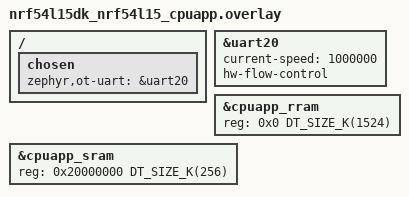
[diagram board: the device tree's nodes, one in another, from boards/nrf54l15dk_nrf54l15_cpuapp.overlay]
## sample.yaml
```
sample:
  description: Test OpenThread Co-Processor
  name: OpenThread Co-Processor sample

tests:
  sample.openthread.coprocessor:
    sysbuild: true
    build_only: true
    tags: ci_build sysbuild ci_samples_openthread
    platform_allow: >
      nrf52833dk/nrf52833
      nrf52840dk/nrf52840
      nrf52840dongle/nrf52840
      nrf21540dk/nrf52840
      nrf54l15dk/nrf54l15/cpuapp
      nrf54l15dk/nrf54l10/cpuapp
      nrf54l15dk/nrf54l05/cpuapp
      nrf54l15dk/nrf54l15/cpuapp/ns
    integration_platforms:
      - nrf52833dk/nrf52833
      - nrf52840dk/nrf52840
      - nrf21540dk/nrf52840
      - nrf52840dongle/nrf52840
      - nrf54l15dk/nrf54l15/cpuapp
      - nrf54l15dk/nrf54l10/cpuapp
      - nrf54l15dk/nrf54l05/cpuapp
      - nrf54l15dk/nrf54l15/cpuapp/ns
  sample.openthread.coprocessor.vendor_hook:
    sysbuild: true
    build_only: true
    tags: ci_build sysbuild ci_samples_openthread
    platform_allow: >
      nrf52833dk/nrf52833
      nrf52840dk/nrf52840
      nrf52840dongle/nrf52840
      nrf21540dk/nrf52840
      nrf54l15dk/nrf54l15/cpuapp
      nrf54l15dk/nrf54l10/cpuapp
      nrf54l15dk/nrf54l05/cpuapp
      nrf54l15dk/nrf54l15/cpuapp/ns
    extra_args: >
      SNIPPET="ci;logging;vendor_hook"
    integration_platforms:
      - nrf52833dk/nrf52833
      - nrf52840dk/nrf52840
      - nrf21540dk/nrf52840
      - nrf52840dongle/nrf52840
      - nrf54l15dk/nrf54l15/cpuapp
      - nrf54l15dk/nrf54l10/cpuapp
      - nrf54l15dk/nrf54l05/cpuapp
      - nrf54l15dk/nrf54l15/cpuapp/ns
  sample.openthread.coprocessor.usb:
    sysbuild: true
    build_only: true
    tags: ci_build sysbuild ci_samples_openthread
    platform_allow: >
      nrf52833dk/nrf52833
      nrf52840dk/nrf52840
      nrf21540dk/nrf52840
    extra_args: >
      SNIPPET="ci;usb"
    integration_platforms:
      - nrf52840dk/nrf52840
      - nrf52833dk/nrf52833
      - nrf21540dk/nrf52840
  sample.openthread.coprocessor.hci:
    sysbuild: true
    build_only: true
    tags: ci_build sysbuild ci_samples_openthread
    extra_args: >
      SNIPPET="ci;hci"
    platform_allow: >
      nrf52840dk/nrf52840
      nrf21540dk/nrf52840
    integration_platforms:
      - nrf52840dk/nrf52840
```

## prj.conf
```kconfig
#
# Copyright (c) 2020 Nordic Semiconductor
#
# SPDX-License-Identifier: LicenseRef-Nordic-5-Clause
#

# Set OpenThread NCP architecture
CONFIG_OPENTHREAD_COPROCESSOR=y
CONFIG_OPENTHREAD_COPROCESSOR_RCP=y

# Nordic feature set
CONFIG_OPENTHREAD_NORDIC_LIBRARY_RCP=y

CONFIG_NET_L2_OPENTHREAD=y

# Generic networking options
CONFIG_NETWORKING=y

# Increase Settings storage size
CONFIG_PM_PARTITION_SIZE_SETTINGS_STORAGE=0x8000

# Disable RTT
CONFIG_USE_SEGGER_RTT=n

# Disable GPIO
CONFIG_GPIO=n
```

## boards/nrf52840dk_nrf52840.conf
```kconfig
#
# Copyright (c) 2024 Nordic Semiconductor
#
# SPDX-License-Identifier: LicenseRef-Nordic-5-Clause
#

# Disable CC3XX entropy
CONFIG_HW_CC3XX=n
CONFIG_ENTROPY_CC3XX=n
```

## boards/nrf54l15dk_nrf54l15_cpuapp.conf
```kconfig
#
# Copyright (c) 2024 Nordic Semiconductor
#
# SPDX-License-Identifier: LicenseRef-Nordic-5-Clause
#

CONFIG_SPI_NOR=n

# Workaround required as Zephyr L2 implies usage of NVS backend for settings.
# It should be removed once the proper fix will be applied in Zephyr.
CONFIG_NVS=n
CONFIG_ZMS=y
CONFIG_SETTINGS_ZMS=y
```

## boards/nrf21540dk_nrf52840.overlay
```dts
/* Copyright (c) 2020 Nordic Semiconductor ASA
 *
 * SPDX-License-Identifier: LicenseRef-Nordic-5-Clause
 */

/* Default Zephyr configuration already provides GPIO support for FEM. */

&uart0 {
	current-speed = <1000000>;
	status = "okay";
	hw-flow-control;
};

&uart1 {
	current-speed = <1000000>;
	status = "okay";
};

/ {
	/*
	* In some default configurations within the nRF Connect SDK,
	* e.g. on nRF52840, the chosen zephyr,entropy node is &cryptocell.
	* This devicetree overlay ensures that default is overridden wherever it
	* is set, as this application uses the RNG node for entropy exclusively.
	*/
	chosen {
		zephyr,entropy = &rng;
		zephyr,ot-uart = &uart0;
	};
};
```

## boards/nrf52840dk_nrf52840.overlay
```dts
/* Copyright (c) 2020 Nordic Semiconductor ASA
 *
 * SPDX-License-Identifier: LicenseRef-Nordic-5-Clause
 */

&uart0 {
	current-speed = <1000000>;
	status = "okay";
	hw-flow-control;
};

&uart1 {
	current-speed = <1000000>;
	status = "okay";
};

/ {
	/*
	* In some default configurations within the nRF Connect SDK,
	* e.g. on nRF52840, the chosen zephyr,entropy node is &cryptocell.
	* This devicetree overlay ensures that default is overridden wherever it
	* is set, as this application uses the RNG node for entropy exclusively.
	*/
	chosen {
		zephyr,entropy = &rng;
		zephyr,ot-uart = &uart0;
	};
};
```

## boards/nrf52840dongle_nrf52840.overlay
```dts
/* Copyright (c) 2024 Nordic Semiconductor ASA
 *
 * SPDX-License-Identifier: LicenseRef-Nordic-5-Clause
 */

/ {
	/*
	 * nRF52840 dongle has pin P0.19 connected to reset. By setting it
	 * in `GPIO_OUTPUT_ACTIVE` mode, reset is pulled to GND,
	 * which results in device rebooting without skipping the bootloader.
	 * openthread_config node enables doing so using `reset bootloader` command.
	 */
	openthread_config: openthread {
		compatible = "openthread,config";
		bootloader-gpios = <&gpio0 19 GPIO_ACTIVE_LOW>;
	};

	chosen {
		zephyr,ot-uart = &cdc_acm_uart;
	};
};
```

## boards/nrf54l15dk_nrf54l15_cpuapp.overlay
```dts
/* Copyright (c) 2024 Nordic Semiconductor ASA
 *
 * SPDX-License-Identifier: LicenseRef-Nordic-5-Clause
 */

&uart20 {
    current-speed = <1000000>;
    status = "okay";
    hw-flow-control;
};

 / {
    chosen {
        zephyr,ot-uart = &uart20;
    };
};

// restore full RRAM and SRAM space - by default some parts are dedicated to FLPR
&cpuapp_rram {
	reg = <0x0 DT_SIZE_K(1524)>;
};

&cpuapp_sram {
	reg = <0x20000000 DT_SIZE_K(256)>;
	ranges = <0x0 0x20000000  DT_SIZE_K(256)>;
};
```

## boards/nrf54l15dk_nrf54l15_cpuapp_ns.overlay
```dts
/* Copyright (c) 2024 Nordic Semiconductor ASA
 *
 * SPDX-License-Identifier: LicenseRef-Nordic-5-Clause
 */

&uart20 {
	current-speed = <1000000>;
	status = "okay";
	hw-flow-control;
};

/ {
	chosen {
		zephyr,ot-uart = &uart20;
	};
};

// restore full RRAM and SRAM space - by default some parts are dedicated to FLPR
&cpuapp_rram {
	reg = <0x0 DT_SIZE_K(1524)>;
};

&cpuapp_sram {
	reg = <0x20000000 DT_SIZE_K(256)>;
	ranges = <0x0 0x20000000  DT_SIZE_K(256)>;
};
```

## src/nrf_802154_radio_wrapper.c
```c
/*
 * Copyright (c) 2020 Nordic Semiconductor ASA
 *
 * SPDX-License-Identifier: LicenseRef-Nordic-5-Clause
 */
#include "nrf_802154_radio_wrapper.h"
#include <nrf_802154.h>
#include <zephyr/device.h>
#include <zephyr/net/ieee802154_radio.h>

static const struct device *const radio_dev =
	DEVICE_DT_GET(DT_CHOSEN(zephyr_ieee802154));
static struct ieee802154_radio_api *radio_api;

bool nrf_802154_radio_wrapper_auto_ack_get(void)
{
	return nrf_802154_auto_ack_get();
}

void nrf_802154_radio_wrapper_auto_ack_set(bool enabled)
{
	nrf_802154_auto_ack_set(enabled);
}

uint16_t nrf_802154_radio_wrapper_hw_capabilities_get(void)
{
	__ASSERT_NO_MSG(device_is_ready(radio_dev));

	radio_api = (struct ieee802154_radio_api *)radio_dev->api;
	__ASSERT_NO_MSG(radio_api != NULL);

	return radio_api->get_capabilities(radio_dev);
}
```

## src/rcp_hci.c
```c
/*
 * Copyright (c) 2023 Nordic Semiconductor ASA
 *
 * SPDX-License-Identifier: LicenseRef-Nordic-5-Clause
 */

#include <errno.h>
#include <stddef.h>
#include <stdio.h>
#include <string.h>

#include <zephyr/arch/cpu.h>
#include <zephyr/sys/byteorder.h>
#include <zephyr/sys/util.h>

#include <zephyr/device.h>
#include <zephyr/init.h>
#include <zephyr/drivers/uart.h>

#include <zephyr/usb/usb_device.h>

#include <zephyr/net_buf.h>
#include <zephyr/bluetooth/bluetooth.h>
#include <zephyr/bluetooth/l2cap.h>
#include <zephyr/bluetooth/hci.h>
#include <zephyr/bluetooth/buf.h>
#include <zephyr/bluetooth/hci_raw.h>

LOG_MODULE_REGISTER(rcp_hci_module, CONFIG_OT_COPROCESSOR_LOG_LEVEL);

static const struct device *const hci_uart_dev = DEVICE_DT_GET(DT_CHOSEN(zephyr_bt_c2h_uart));
static K_THREAD_STACK_DEFINE(tx_thread_stack, CONFIG_BT_HCI_TX_STACK_SIZE);
static struct k_thread tx_thread_data;
static K_FIFO_DEFINE(tx_queue);

/* RX in terms of bluetooth communication */
static K_FIFO_DEFINE(uart_tx_queue);

#define H4_CMD 0x01
#define H4_ACL 0x02
#define H4_SCO 0x03
#define H4_EVT 0x04
#define H4_ISO 0x05

/* Receiver states. */
#define ST_IDLE	   0 /* Waiting for packet type. */
#define ST_HDR	   1 /* Receiving packet header. */
#define ST_PAYLOAD 2 /* Receiving packet payload. */
#define ST_DISCARD 3 /* Dropping packet. */

#define H4_DISCARD_LEN 33

static int h4_read(const struct device *uart, uint8_t *buf, size_t len)
{
	int rx = uart_fifo_read(uart, buf, len);

	LOG_DBG("read %d req %d", rx, len);

	return rx;
}

static bool valid_type(uint8_t type)
{
	return (type == H4_CMD) | (type == H4_ACL) | (type == H4_ISO);
}

/* Function expects that type is validated and only CMD, ISO or ACL will be used. */
static uint32_t get_len(const uint8_t *hdr_buf, uint8_t type)
{
	switch (type) {
	case H4_CMD:
		return ((const struct bt_hci_cmd_hdr *)hdr_buf)->param_len;
	case H4_ISO:
		return bt_iso_hdr_len(
			sys_le16_to_cpu(((const struct bt_hci_iso_hdr *)hdr_buf)->len));
	case H4_ACL:
		return sys_le16_to_cpu(((const struct bt_hci_acl_hdr *)hdr_buf)->len);
	default:
		LOG_ERR("Invalid type: %u", type);
		return 0;
	}
}

/* Function expects that type is validated and only CMD, ISO or ACL will be used. */
static int hdr_len(uint8_t type)
{
	switch (type) {
	case H4_CMD:
		return sizeof(struct bt_hci_cmd_hdr);
	case H4_ISO:
		return sizeof(struct bt_hci_iso_hdr);
	case H4_ACL:
		return sizeof(struct bt_hci_acl_hdr);
	default:
		LOG_ERR("Invalid type: %u", type);
		return 0;
	}
}

static void rx_isr(void)
{
	static struct net_buf *buf;
	static int remaining;
	static uint8_t state;
	static uint8_t type;
	static uint8_t hdr_buf[MAX(sizeof(struct bt_hci_cmd_hdr), sizeof(struct bt_hci_acl_hdr))];
	int read;

	do {
		switch (state) {
		case ST_IDLE:
			/* Get packet type */
			read = h4_read(hci_uart_dev, &type, sizeof(type));
			/* since we read in loop until no data is in the fifo,
			 * it is possible that read = 0.
			 */
			if (read) {
				if (valid_type(type)) {
					/* Get expected header size and switch
					 * to receiving header.
					 */
					remaining = hdr_len(type);
					state = ST_HDR;
				} else {
					LOG_WRN("Unknown header %d", type);
				}
			}
			break;
		case ST_HDR:
			read = h4_read(hci_uart_dev, &hdr_buf[hdr_len(type) - remaining],
				       remaining);
			remaining -= read;
			if (remaining == 0) {
				/* Header received. Allocate buffer and get
				 * payload length. If allocation fails leave
				 * interrupt. On failed allocation state machine
				 * is reset.
				 */
				buf = bt_buf_get_tx(BT_BUF_H4, K_NO_WAIT, &type, sizeof(type));
				if (!buf) {
					LOG_ERR("No available command buffers!");
					state = ST_IDLE;
					return;
				}

				remaining = get_len(hdr_buf, type);

				net_buf_add_mem(buf, hdr_buf, hdr_len(type));
				if (remaining > net_buf_tailroom(buf)) {
					LOG_ERR("Not enough space in buffer");
					net_buf_unref(buf);
					state = ST_DISCARD;
				} else {
					state = ST_PAYLOAD;
				}
			}
			break;
		case ST_PAYLOAD:
			read = h4_read(hci_uart_dev, net_buf_tail(buf), remaining);
			buf->len += read;
			remaining -= read;
			if (remaining == 0) {
				/* Packet received */
				LOG_DBG("putting RX packet in queue.");
				k_fifo_put(&tx_queue, buf);
				state = ST_IDLE;
			}
			break;
		case ST_DISCARD: {
			uint8_t discard[H4_DISCARD_LEN];
			size_t to_read = MIN(remaining, sizeof(discard));

			read = h4_read(hci_uart_dev, discard, to_read);
			remaining -= read;
			if (remaining == 0) {
				state = ST_IDLE;
			}

			break;
		}
		default:
			read = 0;
			__ASSERT_NO_MSG(0);
			break;
		}
	} while (read);
}

static void tx_isr(void)
{
	static struct net_buf *buf;
	int len;

	if (!buf) {
		buf = k_fifo_get(&uart_tx_queue, K_NO_WAIT);
		if (!buf) {
			uart_irq_tx_disable(hci_uart_dev);
			return;
		}
	}

	len = uart_fifo_fill(hci_uart_dev, buf->data, buf->len);
	net_buf_pull(buf, len);
	if (!buf->len) {
		net_buf_unref(buf);
		buf = NULL;
	}
}

static void bt_uart_isr(const struct device *unused, void *user_data)
{
	ARG_UNUSED(unused);
	ARG_UNUSED(user_data);

	if (!(uart_irq_rx_ready(hci_uart_dev) || uart_irq_tx_ready(hci_uart_dev))) {
		LOG_DBG("spurious interrupt");
	}

	if (uart_irq_tx_ready(hci_uart_dev)) {
		tx_isr();
	}

	if (uart_irq_rx_ready(hci_uart_dev)) {
		rx_isr();
	}
}

static void tx_thread(void *p1, void *p2, void *p3)
{
	while (1) {
		struct net_buf *buf;
		int err;

		/* Wait until a buffer is available */
		buf = k_fifo_get(&tx_queue, K_FOREVER);
		/* Pass buffer to the stack */
		err = bt_send(buf);
		if (err) {
			LOG_ERR("Unable to send (err %d)", err);
			net_buf_unref(buf);
		}

		/* Give other threads a chance to run if tx_queue keeps getting
		 * new data all the time.
		 */
		k_yield();
	}
}

static int h4_send(struct net_buf *buf)
{
	LOG_DBG("buf %p type %u len %u", buf, bt_buf_get_type(buf), buf->len);

	k_fifo_put(&uart_tx_queue, buf);
	uart_irq_tx_enable(hci_uart_dev);

	return 0;
}

#if defined(CONFIG_BT_CTLR_ASSERT_HANDLER)
void bt_ctlr_assert_handle(char *file, uint32_t line)
{
	uint32_t len = 0U, pos = 0U;

	/* Disable interrupts, this is unrecoverable */
	(void)irq_lock();

	uart_irq_rx_disable(hci_uart_dev);
	uart_irq_tx_disable(hci_uart_dev);

	if (file) {
		while (file[len] != '\0') {
			if (file[len] == '/') {
				pos = len + 1;
			}
			len++;
		}
		file += pos;
		len -= pos;
	}

	uart_poll_out(hci_uart_dev, H4_EVT);
	/* Vendor-Specific debug event */
	uart_poll_out(hci_uart_dev, 0xff);
	/* 0xAA + strlen + \0 + 32-bit line number */
	uart_poll_out(hci_uart_dev, 1 + len + 1 + 4);
	uart_poll_out(hci_uart_dev, 0xAA);

	if (len) {
		while (*file != '\0') {
			uart_poll_out(hci_uart_dev, *file);
			file++;
		}
		uart_poll_out(hci_uart_dev, 0x00);
	}

	uart_poll_out(hci_uart_dev, line >> 0 & 0xff);
	uart_poll_out(hci_uart_dev, line >> 8 & 0xff);
	uart_poll_out(hci_uart_dev, line >> 16 & 0xff);
	uart_poll_out(hci_uart_dev, line >> 24 & 0xff);

	while (1) {
	}
}
#endif /* CONFIG_BT_CTLR_ASSERT_HANDLER */

static int hci_uart_init(void)
{
	LOG_DBG("");

	if (!device_is_ready(hci_uart_dev)) {
		LOG_ERR("HCI UART %s is not ready", hci_uart_dev->name);
		return -EINVAL;
	}

	uart_irq_rx_disable(hci_uart_dev);
	uart_irq_tx_disable(hci_uart_dev);

	uart_irq_callback_set(hci_uart_dev, bt_uart_isr);

	uart_irq_rx_enable(hci_uart_dev);

	return 0;
}

void run_hci(void)
{
	int err = 0;

	__ASSERT(hci_uart_dev, "UART device is NULL");
	/* incoming events and data from the controller */
	static K_FIFO_DEFINE(rx_queue);

	/* Enable the raw interface, this will in turn open the HCI driver */
	bt_enable_raw(&rx_queue);

	if (IS_ENABLED(CONFIG_BT_WAIT_NOP)) {
		/* Issue a Command Complete with NOP */
		int i;

		const struct {
			const uint8_t h4;
			const struct bt_hci_evt_hdr hdr;
			const struct bt_hci_evt_cmd_complete cc;
		} __packed cc_evt = {
			.h4 = H4_EVT,
			.hdr = {
					.evt = BT_HCI_EVT_CMD_COMPLETE,
					.len = sizeof(struct bt_hci_evt_cmd_complete),
				},
			.cc = {
					.ncmd = 1,
					.opcode = sys_cpu_to_le16(BT_OP_NOP),
				},
		};

		for (i = 0; i < sizeof(cc_evt); i++) {
			uart_poll_out(hci_uart_dev, *(((const uint8_t *)&cc_evt) + i));
		}
	}

	/* Spawn the TX thread and start feeding commands and data to the
	 * controller
	 */
	k_thread_create(&tx_thread_data, tx_thread_stack, K_THREAD_STACK_SIZEOF(tx_thread_stack),
			tx_thread, NULL, NULL, NULL, K_PRIO_COOP(7), 0, K_NO_WAIT);
	k_thread_name_set(&tx_thread_data, "HCI uart TX");

	while (1) {
		struct net_buf *buf;

		buf = k_fifo_get(&rx_queue, K_FOREVER);
		err = h4_send(buf);
		if (err) {
			LOG_ERR("Failed to send");
		}
	}
}

SYS_INIT(hci_uart_init, APPLICATION, CONFIG_KERNEL_INIT_PRIORITY_DEVICE);
```
